# DMA_3 register map
Vendor: Texas Instruments
Peripheral module from a debugger description file (folder msp430).
Registers are 16-bit, access not given, no defined reset value unless marked. A register's access mark holds for its fields unless they carry their own. Offsets are as the file gives them; lines under a group give offsets from that group; [hi:lo] are bit positions; {n}, {i} and the like mark numbered series; 'fields as' and 'values as' point back to an identical list; <NAME> marks a mode.

## DMA
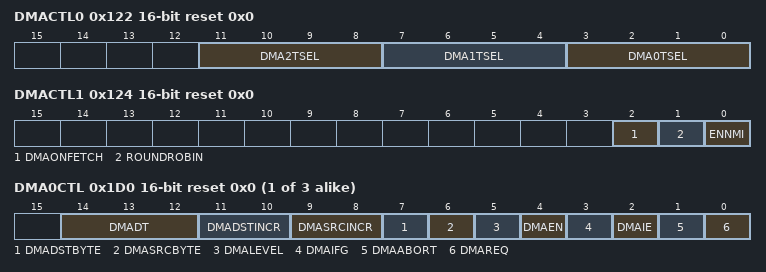
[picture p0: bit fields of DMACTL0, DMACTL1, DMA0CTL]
0x122 DMACTL0 rw reset 0x0 — DMA Module Control 0
  [11:8] DMA2TSEL — DMA channel 2 transfer select bit 0
    0=DMA channel 2 transfer select 0: DMA_REQ; 1=DMA channel 2 transfer select 1: Timer_A CCRIFG.2; 2=DMA channel 2 transfer select 2: Timer_B CCRIFG.2; 3=DMA channel 2 transfer select 3: USCIA0 receive; 4=DMA channel 2 transfer select 4: USCIA0 transmit; 5=DMA channel 2 transfer select 5: DAC12.0IFG; 6=DMA channel 2 transfer select 6: ADC12 (ADC12IFG); 7=DMA channel 2 transfer select 7: Timer_A (TACCR0.IFG); 8=DMA channel 2 transfer select 8: Timer_B (TBCCR0.IFG); 9=DMA channel 2 transfer select 9: USCIA1 receive; 10=DMA channel 2 transfer select 10: USCIA1 transmit; 11=DMA channel 2 transfer select 11: Multiplier ready; 12=DMA channel 2 transfer select 12: USCIB0 receive; 13=DMA channel 2 transfer select 13: USCIB0 transmit; 14=DMA channel 2 transfer select 14: previous DMA channel DMA1IFG; 15=DMA channel 2 transfer select 15: ext. Trigger (DMAE0)
  [7:4] DMA1TSEL — DMA channel 1 transfer select bit 0
    0=DMA channel 1 transfer select 0: DMA_REQ; 1=DMA channel 1 transfer select 1: Timer_A CCRIFG.2; 2=DMA channel 1 transfer select 2: Timer_B CCRIFG.2; 3=DMA channel 1 transfer select 3: USCIA0 receive; 4=DMA channel 1 transfer select 4: USCIA0 transmit; 5=DMA channel 1 transfer select 5: DAC12.0IFG; 6=DMA channel 1 transfer select 6: ADC12 (ADC12IFG); 7=DMA channel 1 transfer select 7: Timer_A (TACCR0.IFG); 8=DMA channel 1 transfer select 8: Timer_B (TBCCR0.IFG); 9=DMA channel 1 transfer select 9: USCIA1 receive; 10=DMA channel 1 transfer select 10: USCIA1 transmit; 11=DMA channel 1 transfer select 11: Multiplier ready; 12=DMA channel 1 transfer select 12: USCIB0 receive; 13=DMA channel 1 transfer select 13: USCIB0 transmit; 14=DMA channel 1 transfer select 14: previous DMA channel DMA0IFG; 15=DMA channel 1 transfer select 15: ext. Trigger (DMAE0)
  [3:0] DMA0TSEL — DMA channel 0 transfer select bit 0
    0=DMA channel 0 transfer select 0: DMA_REQ (sw); 1=DMA channel 0 transfer select 1: Timer_A (TACCR2.IFG); 2=DMA channel 0 transfer select 2: Timer_B (TBCCR2.IFG); 3=DMA channel 0 transfer select 3: USCIA0 receive; 4=DMA channel 0 transfer select 4: USCIA0 transmit; 5=DMA channel 0 transfer select 5: DAC12_0CTL.DAC12IFG; 6=DMA channel 0 transfer select 6: ADC12 (ADC12IFG); 7=DMA channel 0 transfer select 7: Timer_A (TACCR0.IFG); 8=DMA channel 0 transfer select 8: Timer_B (TBCCR0.IFG); 9=DMA channel 0 transfer select 9: USCIA1 receive; 10=DMA channel 0 transfer select 10: USCIA1 transmit; 11=DMA channel 0 transfer select 11: Multiplier ready; 12=DMA channel 0 transfer select 12: USCIB0 receive; 13=DMA channel 0 transfer select 13: USCIB0 transmit; 14=DMA channel 0 transfer select 14: previous DMA channel DMA2IFG; 15=DMA channel 0 transfer select 15: ext. Trigger (DMAE0)
0x124 DMACTL1 rw reset 0x0 — DMA Module Control 1
  [2] DMAONFETCH — DMA transfer on instruction fetch
  [1] ROUNDROBIN — Round-Robin DMA channel priorities
  [0] ENNMI — Enable NMI interruption of DMA
0x126 DMAIV — DMA Interrupt Vector Word
{0x1D0+0xC*i} DMA{i}CTL rw reset 0x0 (i=0..2) — DMA Channel {i} Control
  [14:12] DMADT — DMA transfer mode bit 0
    0=DMA transfer mode 0: single; 1=DMA transfer mode 1: block; 2=DMA transfer mode 2: interleaved; 3=DMA transfer mode 3: interleaved; 4=DMA transfer mode 4: single; 5=DMA transfer mode 5: block; 6=DMA transfer mode 6: interleaved; 7=DMA transfer mode 7: interleaved
  [11:10] DMADSTINCR — DMA destination increment bit 0
    0=DMA destination increment 0: destination address unchanged; 1=DMA destination increment 1: destination address unchanged; 2=DMA destination increment 2: destination address decremented; 3=DMA destination increment 3: destination address incremented
  [9:8] DMASRCINCR — DMA source increment bit 0
    0=DMA source increment 0: source address unchanged; 1=DMA source increment 1: source address unchanged; 2=DMA source increment 2: source address decremented; 3=DMA source increment 3: source address incremented
  [7] DMADSTBYTE — DMA destination byte
  [6] DMASRCBYTE — DMA source byte
  [5] DMALEVEL — DMA level sensitive trigger select
  [4] DMAEN — DMA enable
  [3] DMAIFG — DMA interrupt flag
  [2] DMAIE — DMA interrupt enable
  [1] DMAABORT — DMA transfer aborted by NMI
  [0] DMAREQ — Initiate DMA transfer with DMATSEL
{0x1D2+0xC*i} DMA{i}SA 32-bit (i=0..2) — DMA Channel {i} Source Address
{0x1D2+0xC*i} DMA{i}SAL (i=0..2) — DMA Channel {i} Source Address
{0x1D6+0xC*i} DMA{i}DA 32-bit (i=0..2) — DMA Channel {i} Destination Address
{0x1D6+0xC*i} DMA{i}DAL (i=0..2) — DMA Channel {i} Destination Address
{0x1DA+0xC*i} DMA{i}SZ (i=0..2) — DMA Channel {i} Transfer Size
